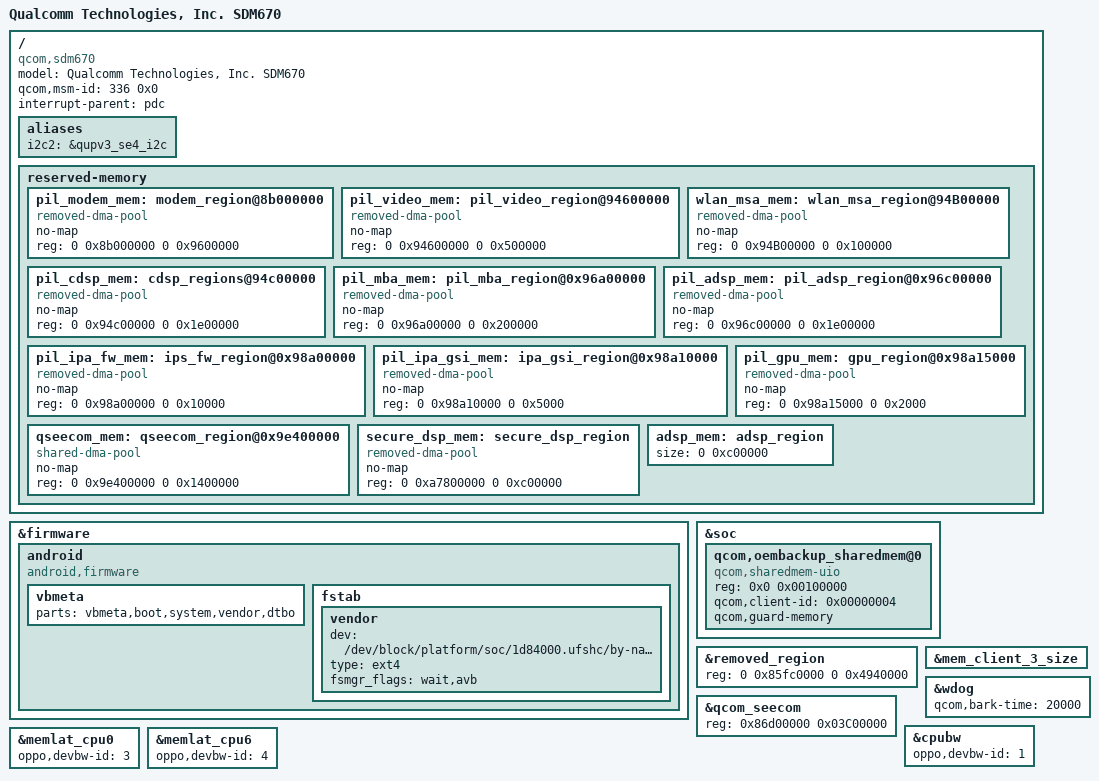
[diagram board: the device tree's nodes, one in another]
/ {
    model = "Qualcomm Technologies, Inc. SDM670";
    compatible = "qcom,sdm670";
    qcom,msm-id = <336 0x0>;
    interrupt-parent = <&pdc>;
    aliases {
        i2c2 = &qupv3_se4_i2c;
    };
};

&firmware {
	android {
		compatible = "android,firmware";

		vbmeta {
			parts = "vbmeta,boot,system,vendor,dtbo";
		};

		fstab {
			vendor {
				dev = "/dev/block/platform/soc/1d84000.ufshc/by-name/vendor";
				type = "ext4";
				fsmgr_flags = "wait,avb";
			};
		};
	};
};

/ {
    reserved-memory {
        /delete-node/ modem_region@8b000000;

		pil_modem_mem: modem_region@8b000000 {
			compatible = "removed-dma-pool";
			no-map;
			reg = <0 0x8b000000 0 0x9600000>;
		};

        /delete-node/ pil_video_region@92e00000;

        pil_video_mem: pil_video_region@94600000 {
            compatible = "removed-dma-pool";
            no-map;
            reg = <0 0x94600000 0 0x500000>;
        };

        /delete-node/ wlan_msa_region@93300000;

        wlan_msa_mem: wlan_msa_region@94B00000 {
            compatible = "removed-dma-pool";
            no-map;
            reg = <0 0x94B00000 0 0x100000>;
        };

        /delete-node/ cdsp_regions@93400000;

        pil_cdsp_mem: cdsp_regions@94c00000 {
            compatible = "removed-dma-pool";
            no-map;
            reg = <0 0x94c00000 0 0x1e00000>;
        };

        /delete-node/ pil_mba_region@0x93c00000;

        pil_mba_mem: pil_mba_region@0x96a00000 {
            compatible = "removed-dma-pool";
            no-map;
            reg = <0 0x96a00000 0 0x200000>;
        };

        /delete-node/ pil_adsp_region@93e00000;

        pil_adsp_mem: pil_adsp_region@0x96c00000 {
            compatible = "removed-dma-pool";
            no-map;
            reg = <0 0x96c00000 0 0x1e00000>;
        };

        /delete-node/ ips_fw_region@0x95c00000;

        pil_ipa_fw_mem: ips_fw_region@0x98a00000 {
            compatible = "removed-dma-pool";
            no-map;
            reg = <0 0x98a00000 0 0x10000>;
        };

        /delete-node/ ipa_gsi_region@0x95c10000;

        pil_ipa_gsi_mem: ipa_gsi_region@0x98a10000 {
            compatible = "removed-dma-pool";
            no-map;
            reg = <0 0x98a10000 0 0x5000>;
        };

        /delete-node/ gpu_region@0x95c15000;

        pil_gpu_mem: gpu_region@0x98a15000 {
            compatible = "removed-dma-pool";
            no-map;
            reg = <0 0x98a15000 0 0x2000>;
        };

        /delete-node/ qseecom_region@0x9e400000;

        qseecom_mem: qseecom_region@0x9e400000 {
            compatible = "shared-dma-pool";
                        no-map;
            reg = <0 0x9e400000 0 0x1400000>;
                };

        secure_dsp_mem: secure_dsp_region {
            compatible = "removed-dma-pool";
            no-map;
            reg = <0 0xa7800000 0 0xc00000>;
        };

        adsp_mem: adsp_region {
            size = <0 0xc00000>;
        };
    };
};

&soc {
    qcom,oembackup_sharedmem@0 {
        compatible = "qcom,sharedmem-uio";
        reg = <0x0 0x00100000>;
        reg-names = "oembackup";
        qcom,client-id = <0x00000004>;
        qcom,guard-memory;
    };
};

&removed_region {
    reg = <0 0x85fc0000 0 0x4940000>;
};

&mem_client_3_size {
    /delete-property/ qcom,allocate-boot-time;
};

&qcom_seecom {
    reg = <0x86d00000 0x03C00000>;
};

&wdog {
    qcom,bark-time = <20000>;
};

&cpubw {
    oppo,devbw-id = <1>;
};

&memlat_cpu0  {
    oppo,devbw-id = <3>;
};

&memlat_cpu6  {
    oppo,devbw-id = <4>;
};
